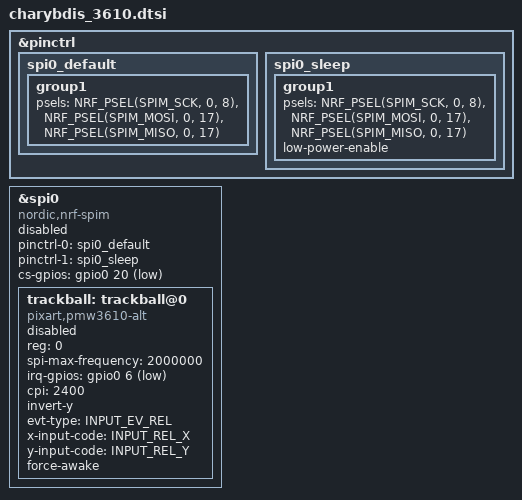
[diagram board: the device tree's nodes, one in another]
#include <zephyr/dt-bindings/input/input-event-codes.h>

&pinctrl {
    spi0_default: spi0_default {
        group1 {
            psels = <NRF_PSEL(SPIM_SCK, 0, 8)>,
                <NRF_PSEL(SPIM_MOSI, 0, 17)>,
                <NRF_PSEL(SPIM_MISO, 0, 17)>;
        };
    };

    spi0_sleep: spi0_sleep {
        group1 {
            psels = <NRF_PSEL(SPIM_SCK, 0, 8)>,
                <NRF_PSEL(SPIM_MOSI, 0, 17)>,
                <NRF_PSEL(SPIM_MISO, 0, 17)>;
            low-power-enable;
        };
    };
};

&spi0 {
    status = "disabled";
    compatible = "nordic,nrf-spim";
    pinctrl-0 = <&spi0_default>;
    pinctrl-1 = <&spi0_sleep>;
    pinctrl-names = "default", "sleep";
    cs-gpios = <&gpio0 20 GPIO_ACTIVE_LOW>;

    trackball: trackball@0 {
        status = "disabled";
        /* badjeff driver on main/zmk-0.4 renamed its compatible to avoid
           clashing with Zephyr's upstream "pixart,pmw3610" driver. */
        compatible = "pixart,pmw3610-alt";
        reg = <0>;
        spi-max-frequency = <2000000>;
        irq-gpios = <&gpio0 6 (GPIO_ACTIVE_LOW | GPIO_PULL_UP)>;
        cpi = <2400>;
        /* Axis orientation. Was swap-xy + invert-x + invert-y, i.e. (-y, -x);
           now rotated 90 degrees to (x, -y). For the opposite 90 degree
           direction use invert-x instead of invert-y. */
        invert-y;
        evt-type = <INPUT_EV_REL>;
        x-input-code = <INPUT_REL_X>;
        y-input-code = <INPUT_REL_Y>;
        /* Stay in RUN mode while ZMK is active; otherwise the sensor downshifts
           to slow REST sampling after a short pause and the first movement
           afterwards lags. Normal downshift resumes when ZMK goes idle. */
        force-awake;
    };
};
